# STM32H573 register map
File version: 1.8
CPU: CM33 r0p0, little endian, MPU, FPU, 4 interrupt priority bits
Registers are 32-bit, read-write, reset 0x0 unless marked. A register's access mark holds for its fields unless they carry their own. Offsets are from the block's base; [hi:lo] are bit positions; {n}, {i} and the like mark numbered series.

## ICACHE — Instruction cache
Base 0x40030400
Same registers: SEC_ICACHE 0x50030400
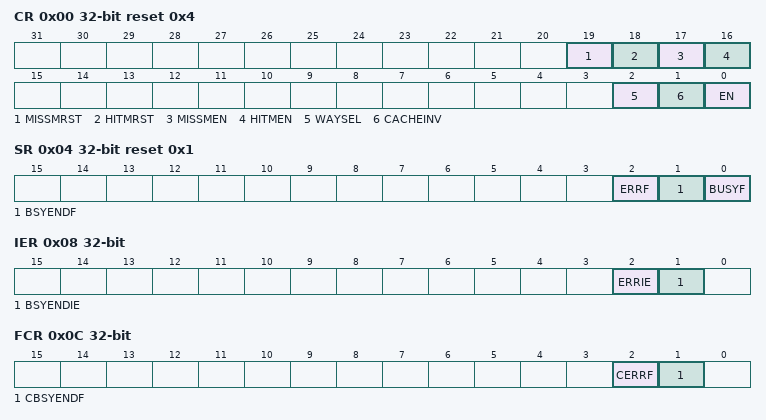
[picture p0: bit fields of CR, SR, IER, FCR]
0x00 CR access per field reset 0x4 — ICACHE control register
  [19] MISSMRST rw — miss monitor reset
  [18] HITMRST rw — hit monitor reset
  [17] MISSMEN rw — miss monitor enable
  [16] HITMEN rw — hit monitor enable
  [2] WAYSEL rw — cache associativity mode selection This bit allows user to choose ICACHE set-associativity. It can be written by software only when cache is disabled (EN = 0).
  [1] CACHEINV wo — cache invalidation Set by software and cleared by hardware when the BUSYF flag is set (during cache maintenance operation). Writing 0 has no effect.
  [0] EN rw — enable
0x04 SR ro reset 0x1 — ICACHE status register
  [2] ERRF — cache error flag
  [1] BSYENDF — busy end flag
  [0] BUSYF — busy flag
0x08 IER — ICACHE interrupt enable register
  [2] ERRIE — interrupt enable on cache error Set by software to enable an interrupt generation in case of cache functional error (cacheable write access)
  [1] BSYENDIE — interrupt enable on busy end Set by software to enable an interrupt generation at the end of a cache invalidate operation.
0x0C FCR wo — ICACHE flag clear register
  [2] CERRF — clear cache error flag Set by software.
  [1] CBSYENDF — clear busy end flag Set by software.
0x10 HMONR ro — ICACHE hit monitor register
  [31:0] HITMON — cache hit monitor counter
0x14 MMONR ro — ICACHE miss monitor register
  [15:0] MISSMON — cache miss monitor counter
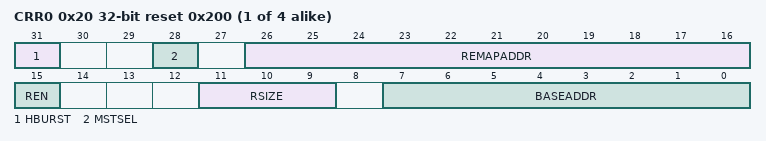
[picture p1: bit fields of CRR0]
{0x20+4i} CRR{i} reset 0x200 (i=0..3) — ICACHE region {i} configuration register
  [31] HBURST — output burst type for region x
  [28] MSTSEL — AHB cache master selection for region x
  [26:16] REMAPADDR — remapped address for region x This field replaces the alias address defined by BASEADDR field. The only useful bits are [31:RI], where 21 less than or equal RI less than or equal 27 is the number of bits of RSIZE (see ). If the programmed value has more LSBs, the useless bits are ignored.
  [15] REN — enable for region x
  [11:9] RSIZE — size for region x
  [7:0] BASEADDR — base address for region x This alias address is replaced by REMAPADDR field. The only useful bits are [28:RI], where 21 less than or equal RI less than or equal 27 is the number of bits of RSIZE (see ). If the programmed value has more LSBs, the useless bits are ignored.

## PKA — Private key accelerator
Base 0x420C2000
Same registers: SEC_PKA 0x520C2000
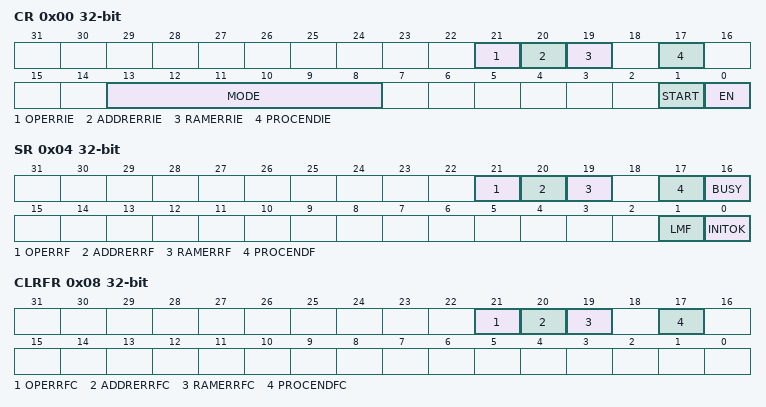
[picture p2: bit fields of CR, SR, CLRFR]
0x00 CR — PKA control register
  [21] OPERRIE — Operation error interrupt enable
  [20] ADDRERRIE — Address error interrupt enable
  [19] RAMERRIE — RAM error interrupt enable
  [17] PROCENDIE — End of operation interrupt enable
  [13:8] MODE — PKA operation code When an operation not listed here is written by the application with EN bit set, OPERRF bit is set in PKA_SR register, and the write to MODE bitfield is ignored. When PKA is configured in limited mode (LMF = 1 in PKA_SR), writing a MODE different from 0x26 with EN bit to 1 triggers OPERRF bit to be set and write to MODE bit is ignored.
  [1] START — start the operation Writing 1 to this bit starts the operation which is selected by MODE[5:0], using the operands and data already written to the PKA RAM. This bit is always read as 0. When an illegal operation is selected while START bit is set no operation is started, and OPERRF bit is set in PKA_SR. START is ignored if PKA is busy.
  [0] EN — PKA enable. When an illegal operation is selected while EN=1 OPERRF bit is set in PKA_SR. See PKA_CR.MODE bitfield for details. When EN=0 PKA RAM can still be accessed by the application.
0x04 SR ro — PKA status register
  [21] OPERRF — Operation error flag This bit is cleared using OPERRFC bit in PKA_CLRFR.
  [20] ADDRERRF — Address error flag This bit is cleared using ADDRERRFC bit in PKA_CLRFR.
  [19] RAMERRF — PKA RAM error flag This bit is cleared using RAMERRFC bit in PKA_CLRFR.
  [17] PROCENDF — PKA End of Operation flag
  [16] BUSY — PKA operation is in progress This bit is set to 1 whenever START bit in the PKA_CR is set. It is automatically cleared when the computation is complete, meaning that PKA RAM can be safely accessed and a new operation can be started. If PKA is started with a wrong opcode, it is busy for a couple of cycles, then it aborts automatically the operation and go back to ready (BUSY bit is set to 0).
  [1] LMF — Limited mode flag This bit is updated when EN bit in PKA_CR is set
  [0] INITOK — PKA initialization OK This bit is asserted when PKA initialization is complete. When RNG is not able to output proper random numbers INITOK stays at 0.
0x08 CLRFR wo — PKA clear flag register
  [21] OPERRFC — Clear operation error flag
  [20] ADDRERRFC — Clear address error flag
  [19] RAMERRFC — Clear PKA RAM error flag
  [17] PROCENDFC — Clear PKA End of Operation flag
